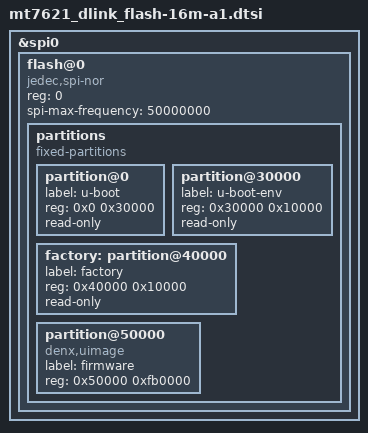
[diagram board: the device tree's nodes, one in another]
// SPDX-License-Identifier: GPL-2.0-or-later OR MIT

&spi0 {
	status = "okay";

	flash@0 {
		compatible = "jedec,spi-nor";
		reg = <0>;
		spi-max-frequency = <50000000>;

		partitions {
			compatible = "fixed-partitions";
			#address-cells = <1>;
			#size-cells = <1>;

			partition@0 {
				label = "u-boot";
				reg = <0x0 0x30000>;
				read-only;
			};

			partition@30000 {
				label = "u-boot-env";
				reg = <0x30000 0x10000>;
				read-only;
			};

			factory: partition@40000 {
				label = "factory";
				reg = <0x40000 0x10000>;
				read-only;
			};

			partition@50000 {
				compatible = "denx,uimage";
				label = "firmware";
				reg = <0x50000 0xfb0000>;
			};
		};
	};
};
